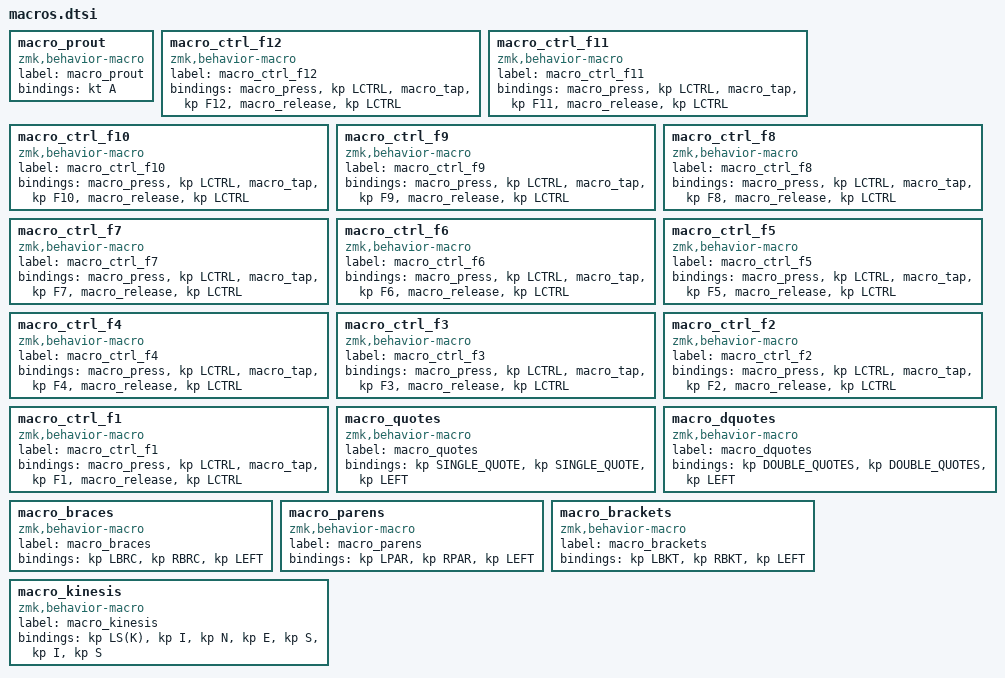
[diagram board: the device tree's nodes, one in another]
macro_prout: macro_prout{
compatible = "zmk,behavior-macro";
label = "macro_prout";
#binding-cells = <0>;
bindings = <&kt A>;
};
macro_ctrl_f12: macro_ctrl_f12{
compatible = "zmk,behavior-macro";
label = "macro_ctrl_f12";
#binding-cells = <0>;
bindings = <&macro_press &kp LCTRL>, <&macro_tap &kp F12>, <&macro_release &kp LCTRL>;
};
macro_ctrl_f11: macro_ctrl_f11{
compatible = "zmk,behavior-macro";
label = "macro_ctrl_f11";
#binding-cells = <0>;
bindings = <&macro_press &kp LCTRL>, <&macro_tap &kp F11>, <&macro_release &kp LCTRL>;
};
macro_ctrl_f10: macro_ctrl_f10{
compatible = "zmk,behavior-macro";
label = "macro_ctrl_f10";
#binding-cells = <0>;
bindings = <&macro_press &kp LCTRL>, <&macro_tap &kp F10>, <&macro_release &kp LCTRL>;
};
macro_ctrl_f9: macro_ctrl_f9{
compatible = "zmk,behavior-macro";
label = "macro_ctrl_f9";
#binding-cells = <0>;
bindings = <&macro_press &kp LCTRL>, <&macro_tap &kp F9>, <&macro_release &kp LCTRL>;
};
macro_ctrl_f8: macro_ctrl_f8{
compatible = "zmk,behavior-macro";
label = "macro_ctrl_f8";
#binding-cells = <0>;
bindings = <&macro_press &kp LCTRL>, <&macro_tap &kp F8>, <&macro_release &kp LCTRL>;
};
macro_ctrl_f7: macro_ctrl_f7{
compatible = "zmk,behavior-macro";
label = "macro_ctrl_f7";
#binding-cells = <0>;
bindings = <&macro_press &kp LCTRL>, <&macro_tap &kp F7>, <&macro_release &kp LCTRL>;
};
macro_ctrl_f6: macro_ctrl_f6{
compatible = "zmk,behavior-macro";
label = "macro_ctrl_f6";
#binding-cells = <0>;
bindings = <&macro_press &kp LCTRL>, <&macro_tap &kp F6>, <&macro_release &kp LCTRL>;
};
macro_ctrl_f5: macro_ctrl_f5{
compatible = "zmk,behavior-macro";
label = "macro_ctrl_f5";
#binding-cells = <0>;
bindings = <&macro_press &kp LCTRL>, <&macro_tap &kp F5>, <&macro_release &kp LCTRL>;
};
macro_ctrl_f4: macro_ctrl_f4{
compatible = "zmk,behavior-macro";
label = "macro_ctrl_f4";
#binding-cells = <0>;
bindings = <&macro_press &kp LCTRL>, <&macro_tap &kp F4>, <&macro_release &kp LCTRL>;
};
macro_ctrl_f3: macro_ctrl_f3{
compatible = "zmk,behavior-macro";
label = "macro_ctrl_f3";
#binding-cells = <0>;
bindings = <&macro_press &kp LCTRL>, <&macro_tap &kp F3>, <&macro_release &kp LCTRL>;
};
macro_ctrl_f2: macro_ctrl_f2{
compatible = "zmk,behavior-macro";
label = "macro_ctrl_f2";
#binding-cells = <0>;
bindings = <&macro_press &kp LCTRL>, <&macro_tap &kp F2>, <&macro_release &kp LCTRL>;
};
macro_ctrl_f1: macro_ctrl_f1{
compatible = "zmk,behavior-macro";
label = "macro_ctrl_f1";
#binding-cells = <0>;
bindings = <&macro_press &kp LCTRL>, <&macro_tap &kp F1>, <&macro_release &kp LCTRL>;
};
macro_quotes: macro_quotes{
compatible = "zmk,behavior-macro";
label = "macro_quotes";
#binding-cells = <0>;
bindings = <&kp SINGLE_QUOTE>, <&kp SINGLE_QUOTE>, <&kp LEFT>;
};
macro_dquotes: macro_dquotes{
compatible = "zmk,behavior-macro";
label = "macro_dquotes";
#binding-cells = <0>;
bindings = <&kp DOUBLE_QUOTES>, <&kp DOUBLE_QUOTES>, <&kp LEFT>;
};
macro_braces: macro_braces{
compatible = "zmk,behavior-macro";
label = "macro_braces";
#binding-cells = <0>;
bindings = <&kp LBRC>, <&kp RBRC>, <&kp LEFT>;
};
macro_parens: macro_parens{
compatible = "zmk,behavior-macro";
label = "macro_parens";
#binding-cells = <0>;
bindings = <&kp LPAR>, <&kp RPAR>, <&kp LEFT>;
};
macro_brackets: macro_brackets{
compatible = "zmk,behavior-macro";
label = "macro_brackets";
#binding-cells = <0>;
bindings = <&kp LBKT>, <&kp RBKT>, <&kp LEFT>;
};
macro_kinesis: macro_kinesis{
compatible = "zmk,behavior-macro";
label = "macro_kinesis";
#binding-cells = <0>;
bindings = <&kp LS(K)>, <&kp I>, <&kp N>, <&kp E>, <&kp S>, <&kp I>, <&kp S>;
};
